# max32662 register map
Vendor: Maxim-Integrated; Series: ARMCM4; File version: 1.1
MAX32662 32-bit ARM Cortex-M4F microcontroller, 256KB of flash, 80KB of SRAM, 128KB of Boot ROM.
CPU: CM4 r2p1, little endian, MPU, FPU, 3 interrupt priority bits
Registers are 32-bit, read-write, reset 0x0 unless marked. A register's access mark holds for its fields unless they carry their own. Offsets are from the block's base; lines under a group give offsets from that group; [hi:lo] are bit positions; {n}, {i} and the like mark numbered series; 'fields as' and 'values as' point back to an identical list; <NAME> marks a mode.

## Memory map
0x40000000 GCR size 0x400 — Global Control Registers.
0x40000400 SIR size 0x400 — System Initialization Registers.
0x40000800 FCR size 0x400 — Function Control Register.
0x40003000 WDT size 0x400 — Windowed Watchdog Timer
0x40008000 GPIO0 size 0x1000 — Individual I/O for each GPIO
0x40010000 TMR size 0x1000 — Low-Power Configurable Timer
0x40011000 TMR1 size 0x1000 — Low-Power Configurable Timer 1
0x40012000 TMR2 size 0x1000 — Low-Power Configurable Timer 2
0x40013000 TMR3 size 0x1000 — Low-Power Configurable Timer 3
0x4001D000 I2C0 size 0x1000 — Inter-Integrated Circuit.
0x4001E000 I2C1 size 0x1000 — Inter-Integrated Circuit. 1
0x40028000 DMA size 0x1000 — DMA Controller Fully programmable, chaining capable DMA channels.
0x40029000 FLC size 0x1000 — Flash Memory Control.
0x4002A000 ICC0 size 0x800 — Instruction Cache Controller Registers
0x40034000 ADC size 0x1000 — Inter-Integrated Circuit.
0x4003C000 PTG size 0x18 — Pulse Train Generation
0x4003C020 PT size 0x10 — Pulse Train
0x4003C040 PT1 size 0x10 — Pulse Train 1
0x4003C060 PT2 size 0x10 — Pulse Train 2
0x4003C080 PT3 size 0x10 — Pulse Train 3
0x40042000 UART size 0x1000 — UART Low Power Registers
0x40043000 UART1 size 0x1000 — UART Low Power Registers 1
0x40046000 SPI0 size 0x1000 — SPI peripheral.
0x40047000 SPI1 size 0x1000 — SPI peripheral. 1
0x4004D000 TRNG size 0x1000 — Random Number Generator.
0x40060000 I2S size 0x1000 — Inter-IC Sound Interface.
0x40064000 CAN0 size 0x1000 — Controller Area Network Registers
0x40105400 TRIMSIR size 0x400 — Trim System Initilazation Registers
0x40106000 RTC size 0x400 — Real Time Clock and Alarm.
0x40106800 PWRSEQ size 0x400 — Power Sequencer / Low Power Control Register.
0x40106C00 MCR size 0x400 — Misc Control.
0x40205000 AESKEYS size 0x400 — AES Key Registers.
0x40207400 AES size 0x400 — AES Keys.

## Interrupts
1 WWDT (WDT)
3 RTC — RTC interrupt.
4 TRNG — TRNG interrupt.
5 TMR
6 TMR1 — TMR1 IRQ
7 TMR2 — TMR2 IRQ
8 TMR3 — TMR3 IRQ
13 I2C0 — I2C0 IRQ
16 SPI0
17 SPI1 — SPI1 IRQ
20 ADC — ADC IRQ
23 Flash_Controller (FLC) — Flash Controller interrupt.
24 GPIO0 — GPIO0 interrupt.
28 DMA0 (DMA)
29 DMA1 (DMA)
30 DMA2 (DMA)
31 DMA3 (DMA)
36 I2C1 — I2C1 IRQ
59 PT (PTG) — Pulse Train IRQ
99 I2S — I2S IRQ

## AESKEYS — AES Key Registers.
Base 0x40205000
{0x0+4i} KEY{i} (i=0..7) — AES Key {i}.

## AES — AES Keys.
Base 0x40207400
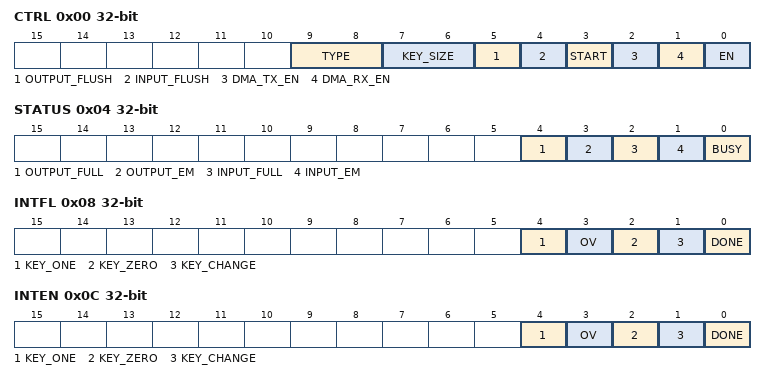
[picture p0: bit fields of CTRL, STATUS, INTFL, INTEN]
0x00 CTRL — AES Control Register
  [9:8] TYPE — Encryption Type Selection
  [7:6] KEY_SIZE — Encryption Key Size
    0=AES128 (128 Bits.); 1=AES192 (192 Bits.); 2=AES256 (256 Bits.)
  [5] OUTPUT_FLUSH — Flush the data output FIFO
  [4] INPUT_FLUSH — Flush the data input FIFO
  [3] START — Start AES Calculation
  [2] DMA_TX_EN — DMA Request To Write Data Input FIFO
  [1] DMA_RX_EN — DMA Request To Read Data Output FIFO
  [0] EN — AES Enable
0x04 STATUS — AES Status Register
  [4] OUTPUT_FULL — Data output FIFO full status
  [3] OUTPUT_EM — Data output FIFO empty status
  [2] INPUT_FULL — Data input FIFO full status
  [1] INPUT_EM — Data input FIFO empty status
  [0] BUSY — AES Busy Status
0x08 INTFL — AES Interrupt Flag Register
  [4] KEY_ONE
  [3] OV — Data Output FIFO Overrun Interrupt
  [2] KEY_ZERO — External AES Key Zero Interrupt
  [1] KEY_CHANGE — External AES Key Changed Interrupt
  [0] DONE — AES Done Interrupt
0x0C INTEN — AES Interrupt Enable Register
  [4] KEY_ONE
  [3] OV — Data Output FIFO Overrun Interrupt Enable
  [2] KEY_ZERO — External AES Key Zero Interrupt Enable
  [1] KEY_CHANGE — External AES Key Changed Interrupt Enable
  [0] DONE — AES Done Interrupt Enable
0x10 FIFO — AES Data Register
  [0] DATA — AES FIFO
